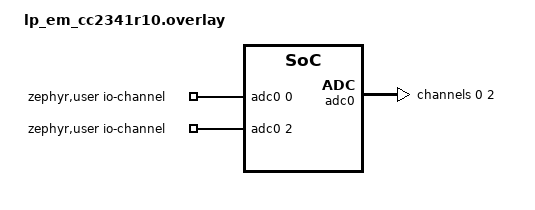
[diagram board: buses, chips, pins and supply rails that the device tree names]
/*
 * Copyright (c) 2026 Texas Instruments Incorporated
 *
 * SPDX-License-Identifier: Apache-2.0
 */

/ {
	zephyr,user {
		/* Channels 0 and 2 are muxed to DIO7 and DIO5 in the board DTS */
		io-channels = <&adc0 0>, <&adc0 2>;
	};
};

&adc0 {
	#address-cells = <1>;
	#size-cells = <0>;

	channel@0 {
		reg = <0>;
		zephyr,gain = "ADC_GAIN_1";
		zephyr,reference = "ADC_REF_INTERNAL";
		zephyr,acquisition-time = <0>;
		zephyr,resolution = <8>;
	};

	channel@2 {
		reg = <2>;
		zephyr,gain = "ADC_GAIN_1";
		zephyr,reference = "ADC_REF_INTERNAL";
		zephyr,acquisition-time = <0>;
		zephyr,resolution = <8>;
	};
};
